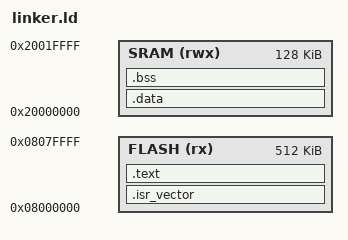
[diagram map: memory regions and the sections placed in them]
ENTRY(Reset_Handler)

MEMORY
{
    FLASH (rx): ORIGIN = 0x08000000, LENGTH = 512K
    SRAM (rwx): ORIGIN = 0x20000000, LENGTH = 128K
}

_estack = ORIGIN(SRAM) + LENGTH(SRAM);

SECTIONS
{
    .isr_vector :
    {
        KEEP(*(.isr_vector))
    } > FLASH

    .text :
    {
        *(.text*)
    } > FLASH

    .data : AT (ADDR(.text) + SIZEOF(.text))
    {
        _sdata = .;
        *(.data*)
        _edata = .;
    } > SRAM

    _sidata = LOADADDR(.data);

    .bss (NOLOAD):
    {
        _sbss = .;
        *(.bss*)
        *(COMMON)
        _ebss = .;
    } > SRAM
}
